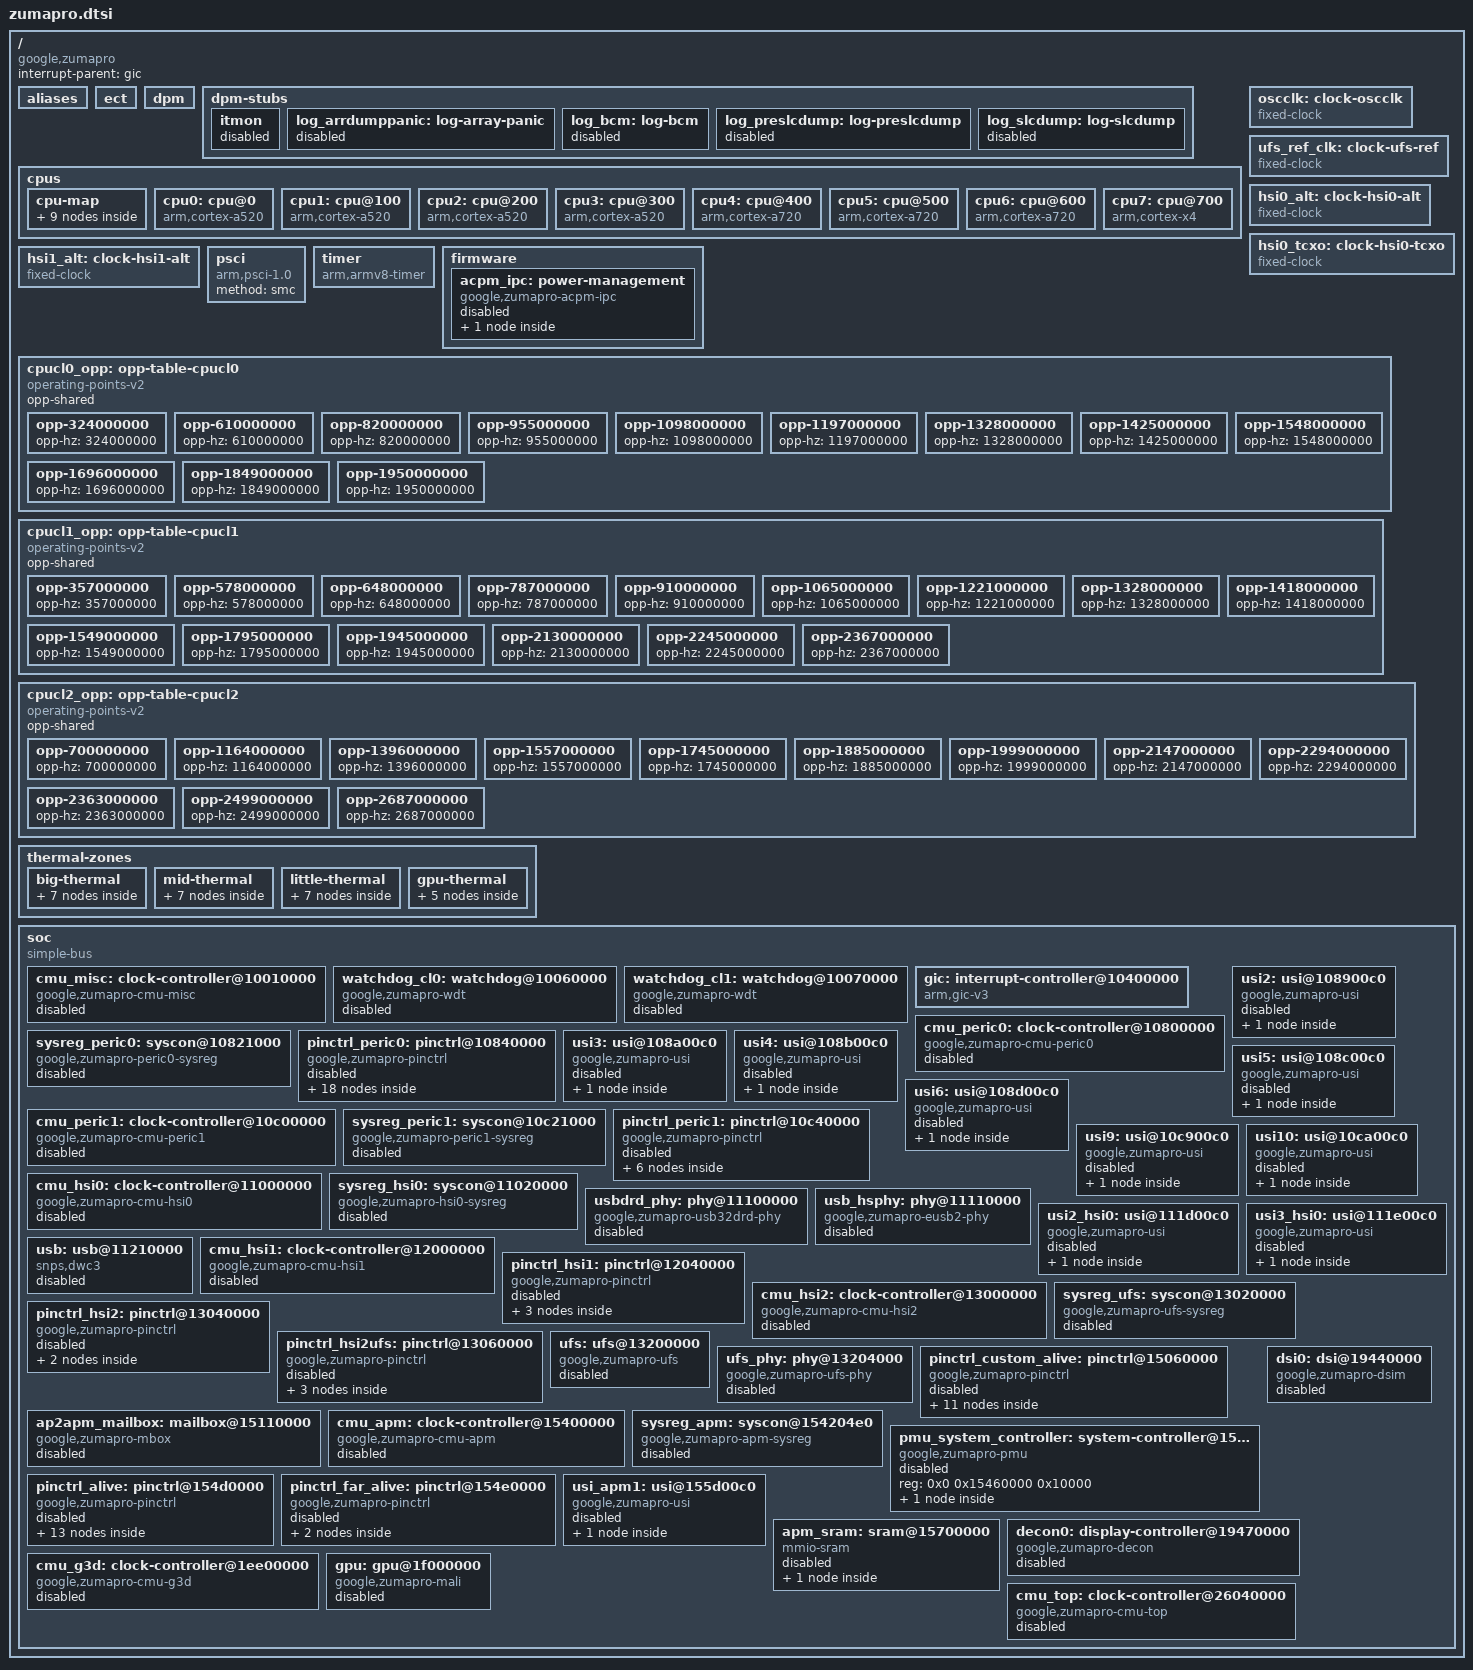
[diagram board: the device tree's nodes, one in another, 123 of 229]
// SPDX-License-Identifier: GPL-2.0-only
/*
 * Google Tensor G4 (Zumapro) core description.
 *
 * Copyright 2022-2023 Google LLC.
 * Copyright (C) 2022 Samsung Electronics Co., Ltd.
 */

#include <dt-bindings/clock/google,zumapro.h>
#include <dt-bindings/clock/google,zumapro-acpm.h>
#include <dt-bindings/interrupt-controller/arm-gic.h>
#include <dt-bindings/soc/samsung,exynos-usi.h>

/ {
	compatible = "google,zumapro";
	#address-cells = <2>;
	#size-cells = <1>;
	interrupt-parent = <&gic>;

	aliases {
		pinctrl0 = &pinctrl_alive;
		pinctrl1 = &pinctrl_custom_alive;
		pinctrl2 = &pinctrl_far_alive;
		pinctrl8 = &pinctrl_hsi1;
		pinctrl9 = &pinctrl_hsi2;
		pinctrl10 = &pinctrl_hsi2ufs;
		pinctrl11 = &pinctrl_peric0;
		pinctrl12 = &pinctrl_peric1;
	};

	/* ABL applies its debug-policy overlay to these nodes. */
	ect { };

	dpm: dpm { };

	/*
	 * Targets of ABL's debug-policy overlay. Keep these driverless and
	 * separate from reserved-memory: disabling a log consumer must not
	 * release its firmware-owned memory to the allocator.
	 */
	dpm-stubs {
		itmon: itmon {
			status = "disabled";
		};

		log_arrdumppanic: log-array-panic {
			status = "disabled";
		};

		log_bcm: log-bcm {
			status = "disabled";
		};

		log_preslcdump: log-preslcdump {
			status = "disabled";
		};

		log_slcdump: log-slcdump {
			status = "disabled";
		};
	};

	cpus {
		#address-cells = <1>;
		#size-cells = <0>;

		cpu-map {
			cluster0 {
				core0 {
					cpu = <&cpu0>;
				};

				core1 {
					cpu = <&cpu1>;
				};

				core2 {
					cpu = <&cpu2>;
				};

				core3 {
					cpu = <&cpu3>;
				};

				core4 {
					cpu = <&cpu4>;
				};

				core5 {
					cpu = <&cpu5>;
				};

				core6 {
					cpu = <&cpu6>;
				};

				core7 {
					cpu = <&cpu7>;
				};
			};
		};

		cpu0: cpu@0 {
			device_type = "cpu";
			compatible = "arm,cortex-a520";
			reg = <0x000>;
			enable-method = "psci";
			capacity-dmips-mhz = <193>;
			dynamic-power-coefficient = <70>;
			#cooling-cells = <2>;
			clocks = <&acpm_ipc ZUMAPRO_CLK_ACPM_DVFS_CPUCL0>;
			operating-points-v2 = <&cpucl0_opp>;
		};

		cpu1: cpu@100 {
			device_type = "cpu";
			compatible = "arm,cortex-a520";
			reg = <0x100>;
			enable-method = "psci";
			capacity-dmips-mhz = <193>;
			dynamic-power-coefficient = <70>;
			#cooling-cells = <2>;
			clocks = <&acpm_ipc ZUMAPRO_CLK_ACPM_DVFS_CPUCL0>;
			operating-points-v2 = <&cpucl0_opp>;
		};

		cpu2: cpu@200 {
			device_type = "cpu";
			compatible = "arm,cortex-a520";
			reg = <0x200>;
			enable-method = "psci";
			capacity-dmips-mhz = <193>;
			dynamic-power-coefficient = <70>;
			#cooling-cells = <2>;
			clocks = <&acpm_ipc ZUMAPRO_CLK_ACPM_DVFS_CPUCL0>;
			operating-points-v2 = <&cpucl0_opp>;
		};

		cpu3: cpu@300 {
			device_type = "cpu";
			compatible = "arm,cortex-a520";
			reg = <0x300>;
			enable-method = "psci";
			capacity-dmips-mhz = <193>;
			dynamic-power-coefficient = <70>;
			#cooling-cells = <2>;
			clocks = <&acpm_ipc ZUMAPRO_CLK_ACPM_DVFS_CPUCL0>;
			operating-points-v2 = <&cpucl0_opp>;
		};

		cpu4: cpu@400 {
			device_type = "cpu";
			compatible = "arm,cortex-a720";
			reg = <0x400>;
			enable-method = "psci";
			capacity-dmips-mhz = <927>;
			dynamic-power-coefficient = <513>;
			#cooling-cells = <2>;
			clocks = <&acpm_ipc ZUMAPRO_CLK_ACPM_DVFS_CPUCL1>;
			operating-points-v2 = <&cpucl1_opp>;
		};

		cpu5: cpu@500 {
			device_type = "cpu";
			compatible = "arm,cortex-a720";
			reg = <0x500>;
			enable-method = "psci";
			capacity-dmips-mhz = <927>;
			dynamic-power-coefficient = <513>;
			#cooling-cells = <2>;
			clocks = <&acpm_ipc ZUMAPRO_CLK_ACPM_DVFS_CPUCL1>;
			operating-points-v2 = <&cpucl1_opp>;
		};

		cpu6: cpu@600 {
			device_type = "cpu";
			compatible = "arm,cortex-a720";
			reg = <0x600>;
			enable-method = "psci";
			capacity-dmips-mhz = <927>;
			dynamic-power-coefficient = <513>;
			#cooling-cells = <2>;
			clocks = <&acpm_ipc ZUMAPRO_CLK_ACPM_DVFS_CPUCL1>;
			operating-points-v2 = <&cpucl1_opp>;
		};

		cpu7: cpu@700 {
			device_type = "cpu";
			compatible = "arm,cortex-x4";
			reg = <0x700>;
			enable-method = "psci";
			capacity-dmips-mhz = <1024>;
			dynamic-power-coefficient = <757>;
			#cooling-cells = <2>;
			clocks = <&acpm_ipc ZUMAPRO_CLK_ACPM_DVFS_CPUCL2>;
			operating-points-v2 = <&cpucl2_opp>;
		};
	};

	oscclk: clock-oscclk {
		compatible = "fixed-clock";
		#clock-cells = <0>;
		clock-frequency = <24576000>;
		clock-output-names = "oscclk";
	};

	/* The GPL PHY calibration uses a 38.4 MHz reference configuration. */
	ufs_ref_clk: clock-ufs-ref {
		compatible = "fixed-clock";
		#clock-cells = <0>;
		clock-frequency = <38400000>;
		clock-output-names = "ufs-ref";
	};

	/* The CAL's nominal rates for HSI0's two board inputs. */
	hsi0_alt: clock-hsi0-alt {
		compatible = "fixed-clock";
		#clock-cells = <0>;
		clock-frequency = <213000000>;
		clock-output-names = "hsi0-alt";
	};

	hsi0_tcxo: clock-hsi0-tcxo {
		compatible = "fixed-clock";
		#clock-cells = <0>;
		clock-frequency = <26000000>;
		clock-output-names = "hsi0-tcxo";
	};

	/* The CAL's nominal I_CLK_HSI1_ALT rate. */
	hsi1_alt: clock-hsi1-alt {
		compatible = "fixed-clock";
		#clock-cells = <0>;
		clock-frequency = <400000000>;
		clock-output-names = "hsi1-alt";
	};

	psci {
		compatible = "arm,psci-1.0";
		method = "smc";
	};

	timer {
		compatible = "arm,armv8-timer";
		interrupts = <GIC_PPI 13 IRQ_TYPE_LEVEL_LOW>,
			     <GIC_PPI 14 IRQ_TYPE_LEVEL_LOW>,
			     <GIC_PPI 11 IRQ_TYPE_LEVEL_LOW>,
			     <GIC_PPI 10 IRQ_TYPE_LEVEL_LOW>;
	};

	firmware {
		acpm_ipc: power-management {
			compatible = "google,zumapro-acpm-ipc";
			#clock-cells = <1>;
			mboxes = <&ap2apm_mailbox>;
			shmem = <&apm_sram>;
			status = "disabled";

			acpm_tmu: thermal-sensor {
				compatible = "google,zumapro-acpm-tmu";
				#thermal-sensor-cells = <1>;
			};
		};
	};

	/*
	 * CPU levels: the APM firmware's own DVFS levels, read on the Pixel 9a
	 * (the little cluster's 324 and 610 MHz are below stock's 820 MHz
	 * floor), up to the 9a's thermal headroom: the levels above each table's
	 * top, listed in it, are left out for that board. A board with more
	 * headroom can add them. The little cluster stops at 1950 MHz, Google's
	 * max-freq for it.
	 */
	cpucl0_opp: opp-table-cpucl0 {
		compatible = "operating-points-v2";
		opp-shared;

		opp-324000000 {
			opp-hz = /bits/ 64 <324000000>;
		};

		opp-610000000 {
			opp-hz = /bits/ 64 <610000000>;
		};

		opp-820000000 {
			opp-hz = /bits/ 64 <820000000>;
		};

		opp-955000000 {
			opp-hz = /bits/ 64 <955000000>;
		};

		opp-1098000000 {
			opp-hz = /bits/ 64 <1098000000>;
		};

		opp-1197000000 {
			opp-hz = /bits/ 64 <1197000000>;
		};

		opp-1328000000 {
			opp-hz = /bits/ 64 <1328000000>;
		};

		opp-1425000000 {
			opp-hz = /bits/ 64 <1425000000>;
		};

		opp-1548000000 {
			opp-hz = /bits/ 64 <1548000000>;
		};

		opp-1696000000 {
			opp-hz = /bits/ 64 <1696000000>;
		};

		opp-1849000000 {
			opp-hz = /bits/ 64 <1849000000>;
		};

		opp-1950000000 {
			opp-hz = /bits/ 64 <1950000000>;
		};

	};

	cpucl1_opp: opp-table-cpucl1 {
		compatible = "operating-points-v2";
		opp-shared;

		opp-357000000 {
			opp-hz = /bits/ 64 <357000000>;
		};

		opp-578000000 {
			opp-hz = /bits/ 64 <578000000>;
		};

		opp-648000000 {
			opp-hz = /bits/ 64 <648000000>;
		};

		opp-787000000 {
			opp-hz = /bits/ 64 <787000000>;
		};

		opp-910000000 {
			opp-hz = /bits/ 64 <910000000>;
		};

		opp-1065000000 {
			opp-hz = /bits/ 64 <1065000000>;
		};

		opp-1221000000 {
			opp-hz = /bits/ 64 <1221000000>;
		};

		opp-1328000000 {
			opp-hz = /bits/ 64 <1328000000>;
		};

		opp-1418000000 {
			opp-hz = /bits/ 64 <1418000000>;
		};

		opp-1549000000 {
			opp-hz = /bits/ 64 <1549000000>;
		};

		opp-1795000000 {
			opp-hz = /bits/ 64 <1795000000>;
		};

		opp-1945000000 {
			opp-hz = /bits/ 64 <1945000000>;
		};

		opp-2130000000 {
			opp-hz = /bits/ 64 <2130000000>;
		};

		opp-2245000000 {
			opp-hz = /bits/ 64 <2245000000>;
		};

		opp-2367000000 {
			opp-hz = /bits/ 64 <2367000000>;
		};

		/* 2450 and 2600 MHz stay off: above the cluster's thermal headroom. */
	};

	cpucl2_opp: opp-table-cpucl2 {
		compatible = "operating-points-v2";
		opp-shared;

		opp-700000000 {
			opp-hz = /bits/ 64 <700000000>;
		};

		opp-1164000000 {
			opp-hz = /bits/ 64 <1164000000>;
		};

		opp-1396000000 {
			opp-hz = /bits/ 64 <1396000000>;
		};

		opp-1557000000 {
			opp-hz = /bits/ 64 <1557000000>;
		};

		opp-1745000000 {
			opp-hz = /bits/ 64 <1745000000>;
		};

		opp-1885000000 {
			opp-hz = /bits/ 64 <1885000000>;
		};

		opp-1999000000 {
			opp-hz = /bits/ 64 <1999000000>;
		};

		opp-2147000000 {
			opp-hz = /bits/ 64 <2147000000>;
		};

		opp-2294000000 {
			opp-hz = /bits/ 64 <2294000000>;
		};

		opp-2363000000 {
			opp-hz = /bits/ 64 <2363000000>;
		};

		opp-2499000000 {
			opp-hz = /bits/ 64 <2499000000>;
		};

		opp-2687000000 {
			opp-hz = /bits/ 64 <2687000000>;
		};

		/*
		 * 2802, 2914, 2943, 2970, 3015 and 3105 MHz stay off: above the
		 * cluster's thermal headroom.
		 */
	};

	thermal-zones {
		big-thermal {
			polling-delay-passive = <250>;
			polling-delay = <1000>;
			thermal-sensors = <&acpm_tmu 0>;

			trips {
				big_alert: big-alert {
					temperature = <80000>;
					hysteresis = <5000>;
					type = "passive";
				};

				big_hot: big-hot {
					temperature = <95000>;
					hysteresis = <10000>;
					type = "passive";
				};

				big_crit: big-crit {
					temperature = <105000>;
					hysteresis = <2000>;
					type = "critical";
				};
			};

			cooling-maps {
				map0 {
					trip = <&big_alert>;
					cooling-device = <&cpu7 0xffffffff 0xffffffff>;
				};

				map1 {
					trip = <&big_hot>;
					cooling-device = <&cpu7 11 0xffffffff>;
				};
			};
		};

		mid-thermal {
			polling-delay-passive = <250>;
			polling-delay = <1000>;
			thermal-sensors = <&acpm_tmu 1>;

			trips {
				mid_alert: mid-alert {
					temperature = <80000>;
					hysteresis = <5000>;
					type = "passive";
				};

				mid_hot: mid-hot {
					temperature = <95000>;
					hysteresis = <10000>;
					type = "passive";
				};

				mid_crit: mid-crit {
					temperature = <105000>;
					hysteresis = <2000>;
					type = "critical";
				};
			};

			cooling-maps {
				map0 {
					trip = <&mid_alert>;
					cooling-device = <&cpu4 0xffffffff 0xffffffff>;
				};

				map1 {
					trip = <&mid_hot>;
					cooling-device = <&cpu4 14 0xffffffff>;
				};
			};
		};

		little-thermal {
			polling-delay-passive = <250>;
			polling-delay = <1000>;
			thermal-sensors = <&acpm_tmu 2>;

			trips {
				little_alert: little-alert {
					temperature = <80000>;
					hysteresis = <5000>;
					type = "passive";
				};

				little_hot: little-hot {
					temperature = <95000>;
					hysteresis = <10000>;
					type = "passive";
				};

				little_crit: little-crit {
					temperature = <105000>;
					hysteresis = <2000>;
					type = "critical";
				};
			};

			cooling-maps {
				map0 {
					trip = <&little_alert>;
					cooling-device = <&cpu0 0xffffffff 0xffffffff>;
				};

				map1 {
					trip = <&little_hot>;
					cooling-device = <&cpu0 11 0xffffffff>;
				};
			};
		};

		gpu-thermal {
			polling-delay-passive = <1000>;
			polling-delay = <2000>;
			thermal-sensors = <&acpm_tmu 3>;

			trips {
				gpu_alert: gpu-alert {
					temperature = <85000>;
					hysteresis = <5000>;
					type = "passive";
				};

				gpu_crit: gpu-crit {
					temperature = <105000>;
					hysteresis = <2000>;
					type = "critical";
				};
			};

			/* panthor's devfreq cooling: step_wise walks the GPU down its OPPs. */
			cooling-maps {
				map0 {
					trip = <&gpu_alert>;
					cooling-device = <&gpu 0xffffffff 0xffffffff>;
				};
			};
		};
	};

	soc: soc {
		compatible = "simple-bus";
		#address-cells = <2>;
		#size-cells = <1>;
		ranges;

		cmu_misc: clock-controller@10010000 {
			compatible = "google,zumapro-cmu-misc";
			reg = <0x0 0x10010000 0x8000>;
			#clock-cells = <1>;
			clocks = <&oscclk>, <&cmu_top CLK_DOUT_MISC_NOC>;
			clock-names = "oscclk", "bus";
			status = "disabled";
		};

		watchdog_cl0: watchdog@10060000 {
			compatible = "google,zumapro-wdt", "google,zuma-wdt";
			reg = <0x0 0x10060000 0x100>;
			interrupts = <GIC_SPI 767 IRQ_TYPE_LEVEL_HIGH>;
			clocks = <&cmu_misc CLK_GOUT_WDT_CLUSTER0>, <&oscclk>;
			clock-names = "watchdog", "watchdog_src";
			timeout-sec = <30>;
			samsung,syscon-phandle = <&pmu_system_controller>;
			samsung,cluster-index = <0>;
			status = "disabled";
		};

		watchdog_cl1: watchdog@10070000 {
			compatible = "google,zumapro-wdt", "google,zuma-wdt";
			reg = <0x0 0x10070000 0x100>;
			interrupts = <GIC_SPI 768 IRQ_TYPE_LEVEL_HIGH>;
			clocks = <&cmu_misc CLK_GOUT_WDT_CLUSTER1>, <&oscclk>;
			clock-names = "watchdog", "watchdog_src";
			timeout-sec = <30>;
			samsung,syscon-phandle = <&pmu_system_controller>;
			samsung,cluster-index = <1>;
			status = "disabled";
		};

		gic: interrupt-controller@10400000 {
			compatible = "arm,gic-v3";
			#interrupt-cells = <3>;
			#address-cells = <0>;
			interrupt-controller;
			reg = <0x0 0x10400000 0x10000>,
			      <0x0 0x10440000 0x200000>;
			interrupts = <GIC_PPI 9 IRQ_TYPE_LEVEL_HIGH>;
		};

		cmu_peric0: clock-controller@10800000 {
			compatible = "google,zumapro-cmu-peric0";
			reg = <0x0 0x10800000 0x8000>;
			#clock-cells = <1>;
			clocks = <&oscclk>, <&cmu_top CLK_DOUT_PERIC0_NOC>,
				 <&cmu_top CLK_DOUT_PERIC0_IP>;
			clock-names = "oscclk", "bus", "ip";
			status = "disabled";
		};

		sysreg_peric0: syscon@10821000 {
			compatible = "google,zumapro-peric0-sysreg", "syscon";
			reg = <0x0 0x10821000 0x1000>;
			clocks = <&cmu_peric0 CLK_GOUT_PERIC0_SYSREG>;
			status = "disabled";
		};

		pinctrl_peric0: pinctrl@10840000 {
			compatible = "google,zumapro-pinctrl";
			reg = <0x0 0x10840000 0x1000>;
			clocks = <&cmu_peric0 CLK_GOUT_GPIO_PERIC0>;
			clock-names = "pclk";
			status = "disabled";

			gpp0: gpp0-gpio-bank {
				gpio-controller;
				#gpio-cells = <2>;
			};

			gpp1: gpp1-gpio-bank {
				gpio-controller;
				#gpio-cells = <2>;
			};

			gpp2: gpp2-gpio-bank {
				gpio-controller;
				#gpio-cells = <2>;
			};

			gpp3: gpp3-gpio-bank {
				gpio-controller;
				#gpio-cells = <2>;
			};

			gpp4: gpp4-gpio-bank {
				gpio-controller;
				#gpio-cells = <2>;
			};

			gpp5: gpp5-gpio-bank {
				gpio-controller;
				#gpio-cells = <2>;
			};

			gpp6: gpp6-gpio-bank {
				gpio-controller;
				#gpio-cells = <2>;
			};

			gpp7: gpp7-gpio-bank {
				gpio-controller;
				#gpio-cells = <2>;
			};

			gpp8: gpp8-gpio-bank {
				gpio-controller;
				#gpio-cells = <2>;
			};

			gpp9: gpp9-gpio-bank {
				gpio-controller;
				#gpio-cells = <2>;
			};

			gpp10: gpp10-gpio-bank {
				gpio-controller;
				#gpio-cells = <2>;
			};

			gpp11: gpp11-gpio-bank {
				gpio-controller;
				#gpio-cells = <2>;
			};

			gpp12: gpp12-gpio-bank {
				gpio-controller;
				#gpio-cells = <2>;
			};

			gpp13: gpp13-gpio-bank {
				gpio-controller;
				#gpio-cells = <2>;
			};

			gpp14: gpp14-gpio-bank {
				gpio-controller;
				#gpio-cells = <2>;
			};

			gpp15: gpp15-gpio-bank {
				gpio-controller;
				#gpio-cells = <2>;
			};

			gpp17: gpp17-gpio-bank {
				gpio-controller;
				#gpio-cells = <2>;
			};

			gpp16: gpp16-gpio-bank {
				gpio-controller;
				#gpio-cells = <2>;
			};
		};

		usi2: usi@108900c0 {
			compatible = "google,zumapro-usi", "samsung,exynos850-usi";
			reg = <0x0 0x108900c0 0x20>;
			clocks = <&cmu_peric0 CLK_GOUT_PERIC0_USI2_PCLK>,
				 <&cmu_peric0 CLK_GOUT_PERIC0_USI2_IPCLK>;
			clock-names = "pclk", "ipclk";
			samsung,sysreg = <&sysreg_peric0 0x4>;
			samsung,mode = <USI_MODE_I2C>;
			#address-cells = <1>;
			#size-cells = <1>;
			ranges = <0x10890000 0x0 0x10890000 0x1000>;
			status = "disabled";

			hsi2c2: i2c@10890000 {
				compatible = "google,zumapro-hsi2c",
					     "samsung,exynosautov9-hsi2c";
				reg = <0x10890000 0xc0>;
				interrupts = <GIC_SPI 643 IRQ_TYPE_LEVEL_HIGH>;
				clocks = <&cmu_peric0 CLK_GOUT_PERIC0_USI2_IPCLK>,
					 <&cmu_peric0 CLK_GOUT_PERIC0_USI2_PCLK>;
				clock-names = "hsi2c", "hsi2c_pclk";
				#address-cells = <1>;
				#size-cells = <0>;
				status = "disabled";
			};
		};

		usi3: usi@108a00c0 {
			compatible = "google,zumapro-usi", "samsung,exynos850-usi";
			reg = <0x0 0x108a00c0 0x20>;
			clocks = <&cmu_peric0 CLK_GOUT_PERIC0_USI3_PCLK>,
				 <&cmu_peric0 CLK_GOUT_PERIC0_USI3_IPCLK>;
			clock-names = "pclk", "ipclk";
			samsung,sysreg = <&sysreg_peric0 0x8>;
			samsung,mode = <USI_MODE_I2C>;
			#address-cells = <1>;
			#size-cells = <1>;
			ranges = <0x108a0000 0x0 0x108a0000 0x1000>;
			status = "disabled";

			hsi2c3: i2c@108a0000 {
				compatible = "google,zumapro-hsi2c",
					     "samsung,exynosautov9-hsi2c";
				reg = <0x108a0000 0xc0>;
				interrupts = <GIC_SPI 644 IRQ_TYPE_LEVEL_HIGH>;
				clocks = <&cmu_peric0 CLK_GOUT_PERIC0_USI3_IPCLK>,
					 <&cmu_peric0 CLK_GOUT_PERIC0_USI3_PCLK>;
				clock-names = "hsi2c", "hsi2c_pclk";
				#address-cells = <1>;
				#size-cells = <0>;
				status = "disabled";
			};
		};

		usi4: usi@108b00c0 {
			compatible = "google,zumapro-usi", "samsung,exynos850-usi";
			reg = <0x0 0x108b00c0 0x20>;
			clocks = <&cmu_peric0 CLK_GOUT_PERIC0_USI4_PCLK>,
				 <&cmu_peric0 CLK_GOUT_PERIC0_USI4_IPCLK>;
			clock-names = "pclk", "ipclk";
			samsung,sysreg = <&sysreg_peric0 0xc>;
			samsung,mode = <USI_MODE_I2C>;
			#address-cells = <1>;
			#size-cells = <1>;
			ranges = <0x108b0000 0x0 0x108b0000 0x1000>;
			status = "disabled";

			hsi2c4: i2c@108b0000 {
				compatible = "google,zumapro-hsi2c",
					     "samsung,exynosautov9-hsi2c";
				reg = <0x108b0000 0xc0>;
				interrupts = <GIC_SPI 645 IRQ_TYPE_LEVEL_HIGH>;
				clocks = <&cmu_peric0 CLK_GOUT_PERIC0_USI4_IPCLK>,
					 <&cmu_peric0 CLK_GOUT_PERIC0_USI4_PCLK>;
				clock-names = "hsi2c", "hsi2c_pclk";
				#address-cells = <1>;
				#size-cells = <0>;
				status = "disabled";
			};
		};

		usi5: usi@108c00c0 {
			compatible = "google,zumapro-usi", "samsung,exynos850-usi";
			reg = <0x0 0x108c00c0 0x20>;
			clocks = <&cmu_peric0 CLK_GOUT_PERIC0_USI5_PCLK>,
				 <&cmu_peric0 CLK_GOUT_PERIC0_USI5_IPCLK>;
			clock-names = "pclk", "ipclk";
			samsung,sysreg = <&sysreg_peric0 0x10>;
			samsung,mode = <USI_MODE_I2C>;
			#address-cells = <1>;
			#size-cells = <1>;
			ranges = <0x108c0000 0x0 0x108c0000 0x1000>;
			status = "disabled";

			hsi2c5: i2c@108c0000 {
				compatible = "google,zumapro-hsi2c",
					     "samsung,exynosautov9-hsi2c";
				reg = <0x108c0000 0xc0>;
				interrupts = <GIC_SPI 646 IRQ_TYPE_LEVEL_HIGH>;
				clocks = <&cmu_peric0 CLK_GOUT_PERIC0_USI5_IPCLK>,
					 <&cmu_peric0 CLK_GOUT_PERIC0_USI5_PCLK>;
				clock-names = "hsi2c", "hsi2c_pclk";
				#address-cells = <1>;
				#size-cells = <0>;
				status = "disabled";
			};
		};

		usi6: usi@108d00c0 {
			compatible = "google,zumapro-usi", "samsung,exynos850-usi";
			reg = <0x0 0x108d00c0 0x20>;
			clocks = <&cmu_peric0 CLK_GOUT_PERIC0_USI6_PCLK>,
				 <&cmu_peric0 CLK_GOUT_PERIC0_USI6_IPCLK>;
			clock-names = "pclk", "ipclk";
			samsung,sysreg = <&sysreg_peric0 0x14>;
			samsung,mode = <USI_MODE_I2C>;
			#address-cells = <1>;
			#size-cells = <1>;
			ranges = <0x108d0000 0x0 0x108d0000 0x1000>;
			status = "disabled";

			hsi2c6: i2c@108d0000 {
				compatible = "google,zumapro-hsi2c",
					     "samsung,exynosautov9-hsi2c";
				reg = <0x108d0000 0xc0>;
				interrupts = <GIC_SPI 647 IRQ_TYPE_LEVEL_HIGH>;
				clocks = <&cmu_peric0 CLK_GOUT_PERIC0_USI6_IPCLK>,
					 <&cmu_peric0 CLK_GOUT_PERIC0_USI6_PCLK>;
				clock-names = "hsi2c", "hsi2c_pclk";
				#address-cells = <1>;
				#size-cells = <0>;
				status = "disabled";
			};
		};

		cmu_peric1: clock-controller@10c00000 {
			compatible = "google,zumapro-cmu-peric1";
			reg = <0x0 0x10c00000 0x8000>;
			#clock-cells = <1>;
			clocks = <&oscclk>, <&cmu_top CLK_DOUT_PERIC1_NOC>,
				 <&cmu_top CLK_DOUT_PERIC1_IP>;
			clock-names = "oscclk", "bus", "ip";
			status = "disabled";
		};

		sysreg_peric1: syscon@10c21000 {
			compatible = "google,zumapro-peric1-sysreg", "syscon";
			reg = <0x0 0x10c21000 0x1000>;
			clocks = <&cmu_peric1 CLK_GOUT_PERIC1_SYSREG>;
			status = "disabled";
		};

		pinctrl_peric1: pinctrl@10c40000 {
			compatible = "google,zumapro-pinctrl";
			reg = <0x0 0x10c40000 0x1000>;
			clocks = <&cmu_peric1 CLK_GOUT_GPIO_PERIC1>;
			clock-names = "pclk";
			status = "disabled";

			gpp19: gpp19-gpio-bank {
				gpio-controller;
				#gpio-cells = <2>;
			};

			gpp20: gpp20-gpio-bank {
				gpio-controller;
				#gpio-cells = <2>;
			};

			gpp21: gpp21-gpio-bank {
				gpio-controller;
				#gpio-cells = <2>;
			};

			gpp24: gpp24-gpio-bank {
				gpio-controller;
				#gpio-cells = <2>;
			};

			gpp22: gpp22-gpio-bank {
				gpio-controller;
				#gpio-cells = <2>;
			};

			gpp23: gpp23-gpio-bank {
				gpio-controller;
				#gpio-cells = <2>;
			};
		};

		usi9: usi@10c900c0 {
			compatible = "google,zumapro-usi", "samsung,exynos850-usi";
			reg = <0x0 0x10c900c0 0x20>;
			clocks = <&cmu_peric1 CLK_GOUT_PERIC1_USI9_PCLK>,
				 <&cmu_peric1 CLK_GOUT_PERIC1_USI9_IPCLK>;
			clock-names = "pclk", "ipclk";
			samsung,sysreg = <&sysreg_peric1 0x4>;
			samsung,mode = <USI_MODE_I2C>;
			#address-cells = <1>;
			#size-cells = <1>;
			ranges = <0x10c90000 0x0 0x10c90000 0x1000>;
			status = "disabled";

			hsi2c9: i2c@10c90000 {
				compatible = "google,zumapro-hsi2c",
					     "samsung,exynosautov9-hsi2c";
				reg = <0x10c90000 0xc0>;
				interrupts = <GIC_SPI 657 IRQ_TYPE_LEVEL_HIGH>;
				clocks = <&cmu_peric1 CLK_GOUT_PERIC1_USI9_IPCLK>,
					 <&cmu_peric1 CLK_GOUT_PERIC1_USI9_PCLK>;
				clock-names = "hsi2c", "hsi2c_pclk";
				#address-cells = <1>;
				#size-cells = <0>;
				status = "disabled";
			};
		};

		usi10: usi@10ca00c0 {
			compatible = "google,zumapro-usi", "samsung,exynos850-usi";
			reg = <0x0 0x10ca00c0 0x20>;
			clocks = <&cmu_peric1 CLK_GOUT_PERIC1_USI10_PCLK>,
				 <&cmu_peric1 CLK_GOUT_PERIC1_USI10_IPCLK>;
			clock-names = "pclk", "ipclk";
			samsung,sysreg = <&sysreg_peric1 0x8>;
			samsung,mode = <USI_MODE_I2C>;
			#address-cells = <1>;
			#size-cells = <1>;
			ranges = <0x10ca0000 0x0 0x10ca0000 0x1000>;
			status = "disabled";

			hsi2c10: i2c@10ca0000 {
				compatible = "google,zumapro-hsi2c",
					     "samsung,exynosautov9-hsi2c";
				reg = <0x10ca0000 0xc0>;
				interrupts = <GIC_SPI 658 IRQ_TYPE_LEVEL_HIGH>;
				clocks = <&cmu_peric1 CLK_GOUT_PERIC1_USI10_IPCLK>,
					 <&cmu_peric1 CLK_GOUT_PERIC1_USI10_PCLK>;
				clock-names = "hsi2c", "hsi2c_pclk";
				#address-cells = <1>;
				#size-cells = <0>;
				status = "disabled";
			};
		};

		cmu_hsi0: clock-controller@11000000 {
			compatible = "google,zumapro-cmu-hsi0";
			reg = <0x0 0x11000000 0x8000>;
			#clock-cells = <1>;
			clocks = <&oscclk>, <&cmu_top CLK_DOUT_HSI0_NOC>,
				 <&cmu_top CLK_DOUT_HSI0_PERI>,
				 <&hsi0_alt>, <&hsi0_tcxo>;
			clock-names = "oscclk", "bus", "peri", "alt", "tcxo";
			status = "disabled";
		};

		sysreg_hsi0: syscon@11020000 {
			compatible = "google,zumapro-hsi0-sysreg", "syscon";
			reg = <0x0 0x11020000 0x10000>;
			clocks = <&cmu_hsi0 CLK_GOUT_HSI0_SYSREG>;
			status = "disabled";
		};

		usbdrd_phy: phy@11100000 {
			compatible = "google,zumapro-usb32drd-phy",
				     "google,zuma-usb32drd-phy";
			reg = <0x0 0x11100000 0x200>;
			#phy-cells = <1>;
			clocks = <&cmu_hsi0 CLK_GOUT_HSI0_USB_SUBCTL>;
			clock-names = "phy";
			phys = <&usb_hsphy>;
			phy-names = "hs";
			samsung,pmu-syscon = <&pmu_system_controller>;
			status = "disabled";
		};

		usb_hsphy: phy@11110000 {
			compatible = "google,zumapro-eusb2-phy",
				     "samsung,exynos2200-eusb2-phy";
			reg = <0x0 0x11110000 0x200>;
			#phy-cells = <0>;
			clocks = <&cmu_hsi0 CLK_GOUT_HSI0_EUSB_REF>,
				 <&cmu_hsi0 CLK_GOUT_HSI0_EUSB_BUS>,
				 <&cmu_hsi0 CLK_GOUT_HSI0_EUSB_CTRL>;
			clock-names = "ref", "bus", "ctrl";
			status = "disabled";
		};

		usi2_hsi0: usi@111d00c0 {
			compatible = "google,zumapro-usi", "samsung,exynos850-usi";
			reg = <0x0 0x111d00c0 0x20>;
			clocks = <&cmu_hsi0 CLK_GOUT_HSI0_USI2_PCLK>,
				 <&cmu_hsi0 CLK_GOUT_HSI0_USI2_IP>;
			clock-names = "pclk", "ipclk";
			samsung,sysreg = <&sysreg_hsi0 0x101c>;
			samsung,mode = <USI_MODE_SPI>;
			#address-cells = <1>;
			#size-cells = <1>;
			ranges = <0x111d0000 0x0 0x111d0000 0x1000>;
			status = "disabled";

			spi20: spi@111d0000 {
				compatible = "google,zumapro-spi", "google,gs101-spi";
				/* USI control starts at 0xc0; do not claim it twice. */
				reg = <0x111d0000 0xc0>;
				interrupts = <GIC_SPI 408 IRQ_TYPE_LEVEL_HIGH>;
				clocks = <&cmu_hsi0 CLK_GOUT_HSI0_USI2_PCLK>,
					 <&cmu_hsi0 CLK_GOUT_HSI0_USI2_IP>;
				clock-names = "spi", "spi_busclk0";
				#address-cells = <1>;
				#size-cells = <0>;
				status = "disabled";
			};
		};

		usi3_hsi0: usi@111e00c0 {
			compatible = "google,zumapro-usi", "samsung,exynos850-usi";
			reg = <0x0 0x111e00c0 0x20>;
			clocks = <&cmu_hsi0 CLK_GOUT_HSI0_USI3_PCLK>,
				 <&cmu_hsi0 CLK_GOUT_HSI0_USI3_IP>;
			clock-names = "pclk", "ipclk";
			samsung,sysreg = <&sysreg_hsi0 0x1020>;
			samsung,mode = <USI_MODE_SPI>;
			#address-cells = <1>;
			#size-cells = <1>;
			ranges = <0x111e0000 0x0 0x111e0000 0x1000>;
			status = "disabled";

			spi21: spi@111e0000 {
				compatible = "google,zumapro-spi", "google,gs101-spi";
				/* USI control starts at 0xc0; do not claim it twice. */
				reg = <0x111e0000 0xc0>;
				interrupts = <GIC_SPI 409 IRQ_TYPE_LEVEL_HIGH>;
				clocks = <&cmu_hsi0 CLK_GOUT_HSI0_USI3_PCLK>,
					 <&cmu_hsi0 CLK_GOUT_HSI0_USI3_IP>;
				clock-names = "spi", "spi_busclk0";
				#address-cells = <1>;
				#size-cells = <0>;
				status = "disabled";
			};
		};

		usb: usb@11210000 {
			compatible = "snps,dwc3";
			reg = <0x0 0x11210000 0x10000>;
			interrupts = <GIC_SPI 402 IRQ_TYPE_LEVEL_HIGH>;
			clocks = <&cmu_hsi0 CLK_GOUT_HSI0_USB_LINK>,
				 <&cmu_hsi0 CLK_MOUT_HSI0_USB20_REF>,
				 <&cmu_hsi0 CLK_GOUT_HSI0_USB_SUSPEND>;
			clock-names = "bus_early", "ref", "suspend";
			phys = <&usbdrd_phy 0>;
			phy-names = "usb2-phy";
			status = "disabled";
		};

		/* The bootloader leaves HSI1 powered; there's no power domain yet. */
		cmu_hsi1: clock-controller@12000000 {
			compatible = "google,zumapro-cmu-hsi1";
			reg = <0x0 0x12000000 0x8000>;
			#clock-cells = <1>;
			clocks = <&oscclk>, <&cmu_top CLK_DOUT_HSI1_NOC>,
				 <&hsi1_alt>;
			clock-names = "oscclk", "bus", "alt";
			status = "disabled";
		};

		pinctrl_hsi1: pinctrl@12040000 {
			compatible = "google,zumapro-pinctrl";
			reg = <0x0 0x12040000 0x1000>;
			clocks = <&cmu_hsi1 CLK_GOUT_GPIO_HSI1>;
			clock-names = "pclk";
			status = "disabled";

			gph0: gph0-gpio-bank {
				gpio-controller;
				#gpio-cells = <2>;
			};

			gph1: gph1-gpio-bank {
				gpio-controller;
				#gpio-cells = <2>;
			};

			gph2: gph2-gpio-bank {
				gpio-controller;
				#gpio-cells = <2>;
			};
		};

		cmu_hsi2: clock-controller@13000000 {
			compatible = "google,zumapro-cmu-hsi2";
			reg = <0x0 0x13000000 0x8000>;
			#clock-cells = <1>;
			clocks = <&oscclk>, <&cmu_top CLK_DOUT_HSI2_NOC>,
				 <&cmu_top CLK_DOUT_HSI2_UFS>,
				 <&cmu_top CLK_DOUT_HSI2_PCIE>;
			clock-names = "oscclk", "bus", "ufs", "pcie";
			status = "disabled";
		};

		sysreg_ufs: syscon@13020000 {
			compatible = "google,zumapro-ufs-sysreg", "syscon";
			reg = <0x0 0x13020000 0x1000>;
			clocks = <&cmu_hsi2 CLK_GOUT_SYSREG_HSI2>;
			status = "disabled";
		};

		pinctrl_hsi2: pinctrl@13040000 {
			compatible = "google,zumapro-pinctrl";
			reg = <0x0 0x13040000 0x1000>;
			clocks = <&cmu_hsi2 CLK_GOUT_GPIO_HSI2>;
			clock-names = "pclk";
			status = "disabled";

			gph3: gph3-gpio-bank {
				gpio-controller;
				#gpio-cells = <2>;
			};

			gph4: gph4-gpio-bank {
				gpio-controller;
				#gpio-cells = <2>;
			};
		};

		pinctrl_hsi2ufs: pinctrl@13060000 {
			compatible = "google,zumapro-pinctrl";
			reg = <0x0 0x13060000 0x1000>;
			clocks = <&cmu_hsi2 CLK_GOUT_GPIO_HSI2UFS>;
			clock-names = "pclk";
			status = "disabled";

			gph5: gph5-gpio-bank {
				gpio-controller;
				#gpio-cells = <2>;
			};

			ufs_reset: ufs-reset-pins {
				samsung,pins = "gph5-1";
				samsung,pin-function = <2>;
				samsung,pin-pud = <0>;
				samsung,pin-con-pdn = <3>;
				samsung,pin-pud-pdn = <0>;
			};

			ufs_refclk: ufs-refclk-pins {
				samsung,pins = "gph5-0";
				samsung,pin-function = <2>;
				samsung,pin-pud = <0>;
				samsung,pin-con-pdn = <3>;
				samsung,pin-pud-pdn = <0>;
				samsung,pin-drv = <2>;
			};
		};

		ufs: ufs@13200000 {
			compatible = "google,zumapro-ufs";
			reg = <0x0 0x13200000 0x200>,
			      <0x0 0x13201100 0x2000>,
			      <0x0 0x13280000 0x8000>,
			      <0x0 0x132a0000 0xa014>;
			reg-names = "hci", "vs_hci", "unipro", "ufsp";
			interrupts = <GIC_SPI 466 IRQ_TYPE_LEVEL_HIGH>;
			clocks = <&cmu_hsi2 CLK_GOUT_UFS_ACLK>,
				 <&cmu_hsi2 CLK_GOUT_UFS_UNIPRO>,
				 <&cmu_hsi2 CLK_GOUT_UFS_FMP>,
				 <&cmu_hsi2 CLK_GOUT_QE_UFS_ACLK>,
				 <&cmu_hsi2 CLK_GOUT_QE_UFS_PCLK>,
				 <&cmu_hsi2 CLK_GOUT_SYSREG_HSI2>;
			clock-names = "core_clk", "sclk_unipro_main", "fmp",
				      "aclk", "pclk", "sysreg";
			freq-table-hz = <0 0>, <0 0>, <0 0>, <0 0>, <0 0>, <0 0>;
			phys = <&ufs_phy>;
			phy-names = "ufs-phy";
			samsung,sysreg = <&sysreg_ufs 0x710>;
			pinctrl-names = "default";
			pinctrl-0 = <&ufs_reset>, <&ufs_refclk>;
			lanes-per-direction = <2>;
			dma-coherent;
			status = "disabled";
		};

		ufs_phy: phy@13204000 {
			compatible = "google,zumapro-ufs-phy";
			reg = <0x0 0x13204000 0x4000>;
			reg-names = "phy-pma";
			samsung,pmu-syscon = <&pmu_system_controller>;
			#phy-cells = <0>;
			clocks = <&ufs_ref_clk>;
			clock-names = "ref_clk";
			status = "disabled";
		};

		pinctrl_custom_alive: pinctrl@15060000 {
			compatible = "google,zumapro-pinctrl";
			reg = <0x0 0x15060000 0x1000>;
			clocks = <&cmu_apm CLK_GOUT_APM_GPIO_CUSTOM_ALIVE>;
			clock-names = "pclk";
			status = "disabled";

			wakeup-interrupt-controller {
				compatible = "google,zumapro-wakeup-eint";
			};

			gpn0: gpn0-gpio-bank {
				gpio-controller;
				#gpio-cells = <2>;
			};

			gpn1: gpn1-gpio-bank {
				gpio-controller;
				#gpio-cells = <2>;
			};

			gpn2: gpn2-gpio-bank {
				gpio-controller;
				#gpio-cells = <2>;
			};

			gpn3: gpn3-gpio-bank {
				gpio-controller;
				#gpio-cells = <2>;
			};

			gpn4: gpn4-gpio-bank {
				gpio-controller;
				#gpio-cells = <2>;
			};

			gpn5: gpn5-gpio-bank {
				gpio-controller;
				#gpio-cells = <2>;
			};

			gpn6: gpn6-gpio-bank {
				gpio-controller;
				#gpio-cells = <2>;
			};

			gpn7: gpn7-gpio-bank {
				gpio-controller;
				#gpio-cells = <2>;
			};

			gpn8: gpn8-gpio-bank {
				gpio-controller;
				#gpio-cells = <2>;
			};

			gpn9: gpn9-gpio-bank {
				gpio-controller;
				#gpio-cells = <2>;
			};
		};

		ap2apm_mailbox: mailbox@15110000 {
			compatible = "google,zumapro-mbox", "google,gs101-mbox";
			reg = <0x0 0x15110000 0x1000>;
			clocks = <&cmu_apm CLK_GOUT_APM_MAILBOX_AP>;
			clock-names = "pclk";
			interrupts = <GIC_SPI 80 IRQ_TYPE_LEVEL_HIGH>;
			#mbox-cells = <0>;
			status = "disabled";
		};

		cmu_apm: clock-controller@15400000 {
			compatible = "google,zumapro-cmu-apm";
			reg = <0x0 0x15400000 0x8000>;
			#clock-cells = <1>;
			clocks = <&oscclk>;
			clock-names = "oscclk";
			status = "disabled";
		};

		sysreg_apm: syscon@154204e0 {
			compatible = "google,zumapro-apm-sysreg", "syscon";
			/* Only the USI mode selectors. */
			reg = <0x0 0x154204e0 0x8>;
			clocks = <&cmu_apm CLK_GOUT_APM_SYSREG>;
			status = "disabled";
		};

		pmu_system_controller: system-controller@15460000 {
			compatible = "google,zumapro-pmu", "google,zuma-pmu";
			reg = <0x0 0x15460000 0x10000>;
			status = "disabled";

			reboot_mode: reboot-mode {
				compatible = "syscon-reboot-mode";
				offset = <0x0810>;
				mode-normal = <0x00>;
				mode-bootloader = <0xfc>;
				status = "disabled";
			};
		};

		pinctrl_alive: pinctrl@154d0000 {
			compatible = "google,zumapro-pinctrl";
			reg = <0x0 0x154d0000 0x1000>;
			clocks = <&cmu_apm CLK_GOUT_APM_GPIO_ALIVE>;
			clock-names = "pclk";
			status = "disabled";

			wakeup-interrupt-controller {
				compatible = "google,zumapro-wakeup-eint";
			};

			gpa0: gpa0-gpio-bank {
				gpio-controller;
				#gpio-cells = <2>;
			};

			gpa1: gpa1-gpio-bank {
				gpio-controller;
				#gpio-cells = <2>;
			};

			gpa2: gpa2-gpio-bank {
				gpio-controller;
				#gpio-cells = <2>;
			};

			gpa3: gpa3-gpio-bank {
				gpio-controller;
				#gpio-cells = <2>;
			};

			gpa4: gpa4-gpio-bank {
				gpio-controller;
				#gpio-cells = <2>;
			};

			gpa6: gpa6-gpio-bank {
				gpio-controller;
				#gpio-cells = <2>;
			};

			gpa7: gpa7-gpio-bank {
				gpio-controller;
				#gpio-cells = <2>;
			};

			gpa8: gpa8-gpio-bank {
				gpio-controller;
				#gpio-cells = <2>;
			};

			gpa9: gpa9-gpio-bank {
				gpio-controller;
				#gpio-cells = <2>;
			};

			gpa10: gpa10-gpio-bank {
				gpio-controller;
				#gpio-cells = <2>;
			};

			gpa11: gpa11-gpio-bank {
				gpio-controller;
				#gpio-cells = <2>;
			};

			gpa12: gpa12-gpio-bank {
				gpio-controller;
				#gpio-cells = <2>;
			};
		};

		pinctrl_far_alive: pinctrl@154e0000 {
			compatible = "google,zumapro-pinctrl";
			reg = <0x0 0x154e0000 0x1000>;
			clocks = <&cmu_apm CLK_GOUT_APM_GPIO_FAR_ALIVE>;
			clock-names = "pclk";
			status = "disabled";

			wakeup-interrupt-controller {
				compatible = "google,zumapro-wakeup-eint";
			};

			gpa5: gpa5-gpio-bank {
				gpio-controller;
				#gpio-cells = <2>;
			};
		};

		usi_apm1: usi@155d00c0 {
			compatible = "google,zumapro-usi", "samsung,exynos850-usi";
			reg = <0x0 0x155d00c0 0x20>;
			clocks = <&cmu_apm CLK_GOUT_APM_USI1_UART_PCLK>,
				 <&cmu_apm CLK_GOUT_APM_USI1_UART_IPCLK>;
			clock-names = "pclk", "ipclk";
			samsung,sysreg = <&sysreg_apm 0x4>;
			samsung,mode = <USI_MODE_UART>;
			samsung,clkreq-on;
			#address-cells = <1>;
			#size-cells = <1>;
			ranges = <0x155d0000 0x0 0x155d0000 0x1000>;
			status = "disabled";

			uart18: serial@155d0000 {
				compatible = "google,zumapro-uart", "google,gs101-uart";
				reg = <0x155d0000 0xc0>;
				interrupts = <GIC_SPI 71 IRQ_TYPE_LEVEL_HIGH>;
				clocks = <&cmu_apm CLK_GOUT_APM_USI1_UART_PCLK>,
					 <&cmu_apm CLK_GOUT_APM_USI1_UART_IPCLK>;
				clock-names = "uart", "clk_uart_baud0";
				samsung,uart-fifosize = <256>;
				status = "disabled";
			};
		};

		apm_sram: sram@15700000 {
			compatible = "mmio-sram";
			reg = <0x0 0x15700000 0x58000>;
			clocks = <&cmu_apm CLK_GOUT_APM_INTMEM_ACLK>;
			#address-cells = <1>;
			#size-cells = <1>;
			ranges = <0x0 0x0 0x15700000 0x58000>;
			no-memory-wc;
			status = "disabled";

			/* The APM firmware's window, as one block. */
			firmware-sram@0 {
				reg = <0x0 0x58000>;
			};
		};

		dsi0: dsi@19440000 {
			compatible = "google,zumapro-dsim", "google,gs201-dsim";
			reg = <0x0 0x19440000 0x300>,
			      <0x0 0x19460100 0x700>,
			      <0x0 0x19460000 0x100>;
			reg-names = "dsi", "dphy", "dphy-extra";
			interrupts = <GIC_SPI 252 IRQ_TYPE_LEVEL_HIGH>;
			#address-cells = <1>;
			#size-cells = <0>;
			status = "disabled";
		};

		/* Scans out what the bootloader set up; no panel or clock control. */
		decon0: display-controller@19470000 {
			compatible = "google,zumapro-decon";
			reg = <0x0 0x19470000 0x2000>, <0x0 0x19900000 0x1000>;
			reg-names = "main", "dma";
			interrupts = <GIC_SPI 243 IRQ_TYPE_LEVEL_HIGH>,
				     <GIC_SPI 242 IRQ_TYPE_LEVEL_HIGH>,
				     <GIC_SPI 241 IRQ_TYPE_LEVEL_HIGH>;
			interrupt-names = "frame_start", "frame_done", "extra";
			status = "disabled";
		};

		/* The bootloader leaves G3D powered; there's no power domain yet. */
		cmu_g3d: clock-controller@1ee00000 {
			compatible = "google,zumapro-cmu-g3d";
			reg = <0x0 0x1ee00000 0x8000>;
			#clock-cells = <1>;
			clocks = <&oscclk>, <&cmu_top CLK_DOUT_G3D_NOCD>,
				 <&cmu_top CLK_DOUT_G3D_GLB>,
				 <&cmu_top CLK_DOUT_G3D_SWITCH>;
			clock-names = "oscclk", "bus", "glb", "switch";
			status = "disabled";
		};

		gpu: gpu@1f000000 {
			compatible = "google,zumapro-mali", "arm,mali-valhall-csf";
			reg = <0x0 0x1f000000 0x480000>;
			interrupts = <GIC_SPI 347 IRQ_TYPE_LEVEL_HIGH>,
				     <GIC_SPI 348 IRQ_TYPE_LEVEL_HIGH>,
				     <GIC_SPI 346 IRQ_TYPE_LEVEL_HIGH>;
			interrupt-names = "job", "mmu", "gpu";
			clocks = <&cmu_g3d CLK_GOUT_G3D_CORE>,
				 <&cmu_g3d CLK_GOUT_G3D_COREGROUP>,
				 <&cmu_g3d CLK_GOUT_G3D_STACKS>;
			clock-names = "core", "coregroup", "stacks";
			#cooling-cells = <2>;
			status = "disabled";
		};

		cmu_top: clock-controller@26040000 {
			compatible = "google,zumapro-cmu-top";
			reg = <0x0 0x26040000 0x8000>;
			#clock-cells = <1>;
			clocks = <&oscclk>;
			clock-names = "oscclk";
			status = "disabled";
		};
	};
};
